CM_ "toyota_townace.dbc - Toyota Town Ace (2025, Taiwan) powertrain + chassis CAN, 500 kbps";
CM_ "Made 2026-11-17 from openpilot branch 2955 daihatsu_granmax_generated.dbc (802309d2f).";
CM_ "The Town Ace is the Toyota badge of the Daihatsu Gran Max (S403/S413); the Gran Max";
CM_ "DBC was itself built from a Town Ace highway capture (220676 frames, 69 IDs).";
CM_ "Changes from the Gran Max DBC, all measured on the car with lowcostPedal t10b_can_signals:";
CM_ "  TRANSMISSION.GEAR now covers all of byte 1 (R N D 2 L), PARK added (byte 0 bit 0).";
CM_ "  HANDBRAKE.HANDBRAKE_ENGAGED moved to byte 0 bit 0 (the old one sat on the checksum).";
CM_ "  WHEEL_SPEED_CLEAN.WHEELSPEED moved to bytes 5-6 (the old 13-bit field overflowed).";
CM_ "  MSG_199 renamed SPEED_2 with the speed in bytes 3-4.";
CM_ "Frame checksum is the Toyota scheme (file name starts with toyota_ so opendbc uses it).";
CM_ "MSG_xxx entries are not decoded. Scales not marked verified are still Ativa values.";

VERSION ""

NS_ :

BS_:

BU_: EON XXX INTERCEPTOR ANY ACTUATOR SAFETY

BO_ 8 STAYALIVE_1: 0 XXX

BO_ 51 STAYALIVE_2: 0 XXX

BO_ 160 MSG_0A0: 5 XXX
 SG_ CHECKSUM : 39|8@0+ (1,0) [0|255] "" XXX

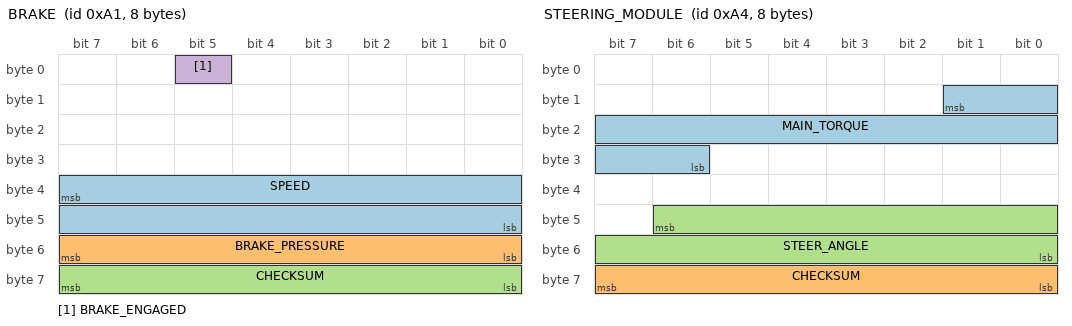
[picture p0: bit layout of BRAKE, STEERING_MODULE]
BO_ 161 BRAKE: 8 XXX
 SG_ SPEED : 39|16@0+ (0.01,0) [0|65535] "km/h" XXX
 SG_ BRAKE_PRESSURE : 48|8@1+ (0.005532,0) [0|255] "" XXX
 SG_ CHECKSUM : 63|8@0+ (1,0) [0|255] "" XXX
 SG_ BRAKE_ENGAGED : 5|1@0+ (1,0) [0|1] "" XXX

BO_ 164 STEERING_MODULE: 8 XXX
 SG_ MAIN_TORQUE : 9|12@0- (1,0) [0|65535] "" XXX
 SG_ CHECKSUM : 63|8@0+ (1,0) [0|255] "" XXX
 SG_ STEER_ANGLE : 46|15@0- (0.10047,0) [-500|500] "" XXX

BO_ 165 MSG_0A5: 4 XXX
 SG_ CHECKSUM : 31|8@0+ (1,0) [0|255] "" XXX

BO_ 308 MSG_134: 6 XXX
 SG_ CHECKSUM : 47|8@0+ (1,0) [0|255] "" XXX

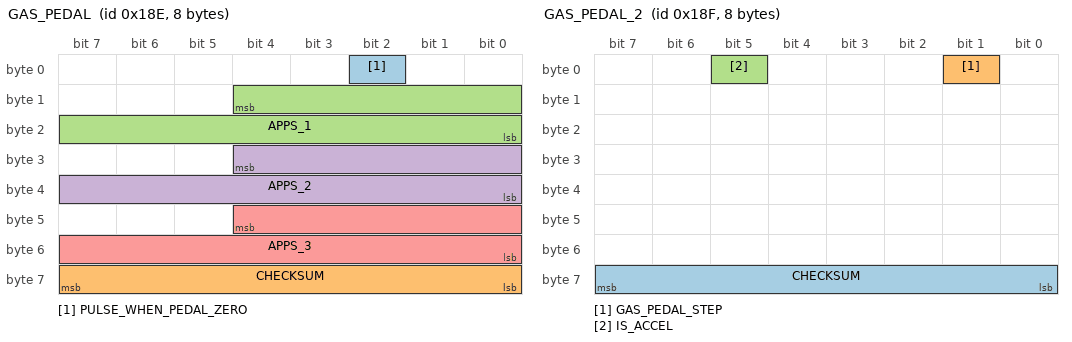
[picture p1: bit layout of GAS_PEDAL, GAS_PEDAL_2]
BO_ 398 GAS_PEDAL: 8 XXX
 SG_ PULSE_WHEN_PEDAL_ZERO : 2|1@0+ (1,0) [0|1] "" XXX
 SG_ CHECKSUM : 63|8@0+ (1,0) [0|255] "" XXX
 SG_ APPS_1 : 12|13@0+ (0.015625,0) [0|100] "%" XXX
 SG_ APPS_2 : 28|13@0+ (0.00006742,0) [0|1023] "" XXX
 SG_ APPS_3 : 44|13@0+ (1,0) [0|8191] "rpm" XXX

BO_ 399 GAS_PEDAL_2: 8 XXX
 SG_ CHECKSUM : 63|8@0+ (1,0) [0|255] "" XXX
 SG_ GAS_PEDAL_STEP : 1|1@0+ (1,0) [0|1] "" XXX
 SG_ IS_ACCEL : 5|1@0+ (1,0) [0|1] "" XXX

BO_ 400 MSG_190: 8 XXX
 SG_ CHECKSUM : 63|8@0+ (1,0) [0|255] "" XXX

BO_ 409 SPEED_2: 8 XXX
 SG_ CHECKSUM : 63|8@0+ (1,0) [0|255] "" XXX
 SG_ SPEED : 31|16@0+ (0.0103,0) [0|675] "km/h" XXX

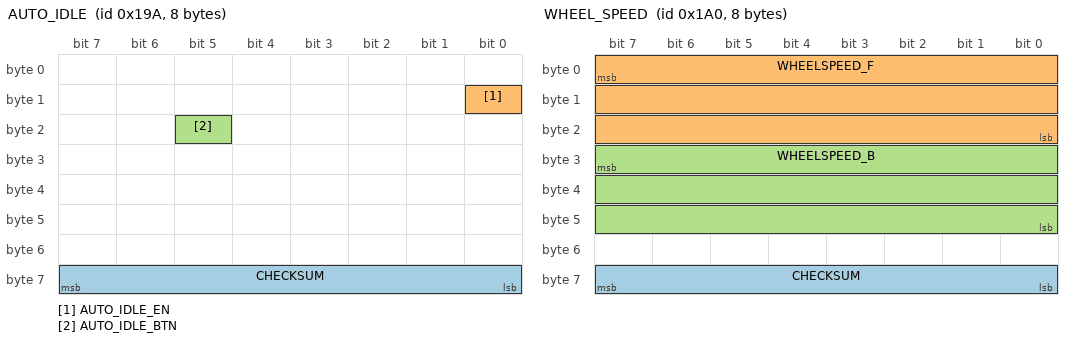
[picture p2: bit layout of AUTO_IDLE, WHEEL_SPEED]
BO_ 410 AUTO_IDLE: 8 XXX
 SG_ CHECKSUM : 63|8@0+ (1,0) [0|255] "" XXX
 SG_ AUTO_IDLE_EN : 8|1@1+ (1,0) [0|511] "" XXX
 SG_ AUTO_IDLE_BTN : 21|1@0+ (1,0) [0|1] "" XXX

BO_ 416 WHEEL_SPEED: 8 XXX
 SG_ CHECKSUM : 63|8@0+ (1,0) [0|255] "" XXX
 SG_ WHEELSPEED_F : 7|24@0+ (0.00001,0) [0|16777215] "" XXX
 SG_ WHEELSPEED_B : 31|24@0+ (0.00000250,0) [0|16777215] "" XXX

BO_ 417 MSG_1A1: 7 XXX
 SG_ CHECKSUM : 55|8@0+ (1,0) [0|255] "" XXX

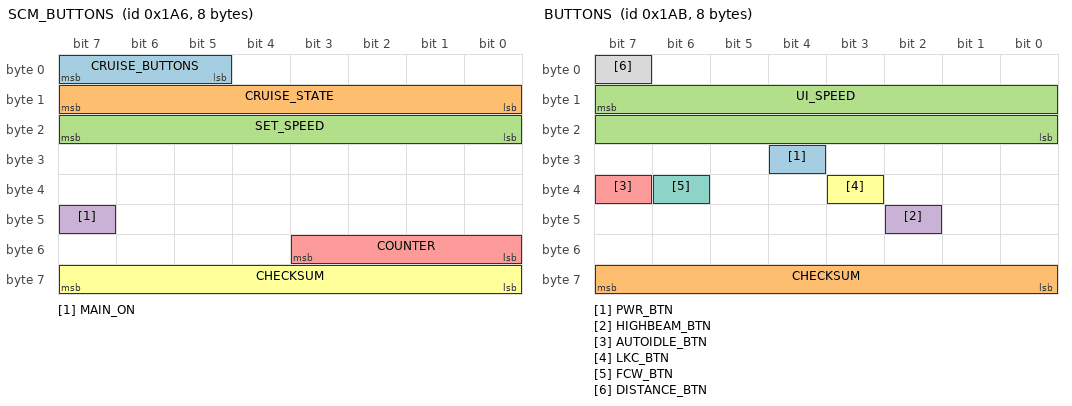
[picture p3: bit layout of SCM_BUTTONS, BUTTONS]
BO_ 422 SCM_BUTTONS: 8 INTERCEPTOR
 SG_ CRUISE_BUTTONS : 7|3@0+ (1,0) [0|7] "" XXX
 SG_ CRUISE_STATE : 15|8@0+ (1,0) [0|4] "" XXX
 SG_ SET_SPEED : 23|8@0+ (1,0) [0|255] "km/h" XXX
 SG_ MAIN_ON : 47|1@0+ (1,0) [0|1] "" XXX
 SG_ COUNTER : 51|4@0+ (1,0) [0|15] "" XXX
 SG_ CHECKSUM : 63|8@0+ (1,0) [0|255] "" XXX

BO_ 427 BUTTONS: 8 XXX
 SG_ PWR_BTN : 28|1@0+ (1,0) [0|1] "" XXX
 SG_ CHECKSUM : 63|8@0+ (1,0) [0|255] "" XXX
 SG_ UI_SPEED : 15|16@0+ (0.01,0) [0|65535] "" XXX
 SG_ HIGHBEAM_BTN : 42|1@0+ (1,0) [0|1] "" XXX
 SG_ AUTOIDLE_BTN : 39|1@0+ (1,0) [0|1] "" XXX
 SG_ LKC_BTN : 35|1@0+ (1,0) [0|1] "" XXX
 SG_ FCW_BTN : 38|1@1+ (1,0) [0|511] "" XXX
 SG_ DISTANCE_BTN : 7|1@0+ (1,0) [0|1] "" XXX

BO_ 429 MSG_1AD: 8 XXX
 SG_ CHECKSUM : 63|8@0+ (1,0) [0|255] "" XXX

BO_ 448 EPS_SHAFT_TORQUE: 4 XXX
 SG_ CHECKSUM : 31|8@0+ (1,0) [0|255] "" XXX
 SG_ STEERING_TORQUE : 8|8@1+ (1,0) [0|255] "" XXX

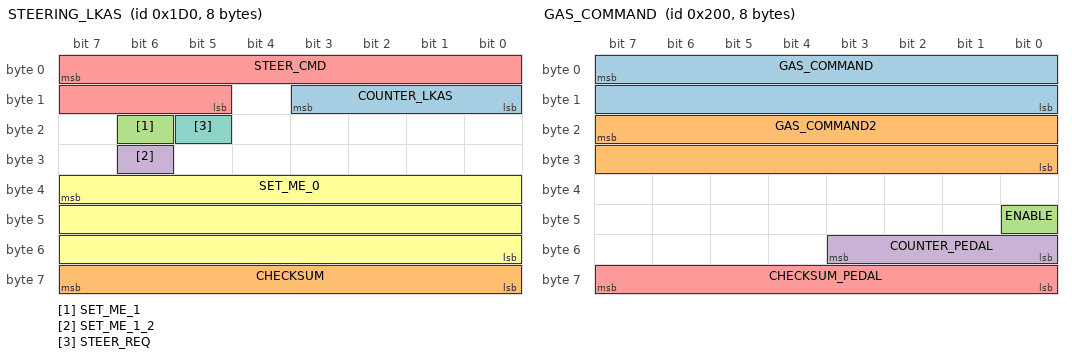
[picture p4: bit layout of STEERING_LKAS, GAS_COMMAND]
BO_ 464 STEERING_LKAS: 8 XXX
 SG_ COUNTER_LKAS : 11|4@0+ (1,0) [0|15] "" XXX
 SG_ CHECKSUM : 63|8@0+ (1,0) [0|255] "" XXX
 SG_ SET_ME_1 : 22|1@0+ (1,0) [0|1] "" XXX
 SG_ SET_ME_1_2 : 30|1@0+ (1,0) [0|1] "" XXX
 SG_ STEER_CMD : 7|11@0- (1,0) [0|255] "" XXX
 SG_ SET_ME_0 : 39|24@0+ (1,0) [0|16777215] "" XXX
 SG_ STEER_REQ : 21|1@0+ (1,0) [0|1] "" XXX

BO_ 496 MSG_1F0: 5 XXX
 SG_ CHECKSUM : 39|8@0+ (1,0) [0|255] "" XXX

BO_ 512 GAS_COMMAND: 8 SAFETY
 SG_ GAS_COMMAND : 7|16@0+ (1,0) [0|1] "" ACTUATOR
 SG_ GAS_COMMAND2 : 23|16@0+ (1,0) [0|1] "" ACTUATOR
 SG_ ENABLE : 40|1@0+ (1,0) [0|1] "" ACTUATOR
 SG_ COUNTER_PEDAL : 51|4@0+ (1,0) [0|15] "" ACTUATOR
 SG_ CHECKSUM_PEDAL : 63|8@0+ (1,0) [0|255] "" ACTUATOR

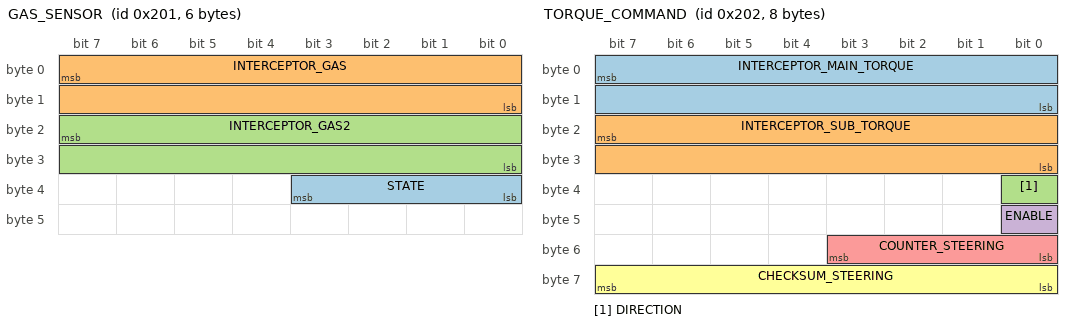
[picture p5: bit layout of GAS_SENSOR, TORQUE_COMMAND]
BO_ 513 GAS_SENSOR: 6 ACTUATOR
 SG_ STATE : 35|4@0+ (1,0) [0|15] "" SAFETY
 SG_ INTERCEPTOR_GAS : 7|16@0+ (0.0007,-0.342) [0|1] "" SAFETY
 SG_ INTERCEPTOR_GAS2 : 23|16@0+ (0.0007,-0.691) [0|1] "" SAFETY

BO_ 514 TORQUE_COMMAND: 8 SAFETY
 SG_ INTERCEPTOR_MAIN_TORQUE : 7|16@0+ (1,0) [0|1] "" ACTUATOR
 SG_ INTERCEPTOR_SUB_TORQUE : 23|16@0+ (1,0) [0|1] "" ACTUATOR
 SG_ DIRECTION : 32|1@0+ (1,0) [0|1] "" ACTUATOR
 SG_ ENABLE : 40|1@0+ (1,0) [0|1] "" ACTUATOR
 SG_ COUNTER_STEERING : 51|4@0+ (1,0) [0|15] "" ACTUATOR
 SG_ CHECKSUM_STEERING : 63|8@0+ (1,0) [0|255] "" ACTUATOR

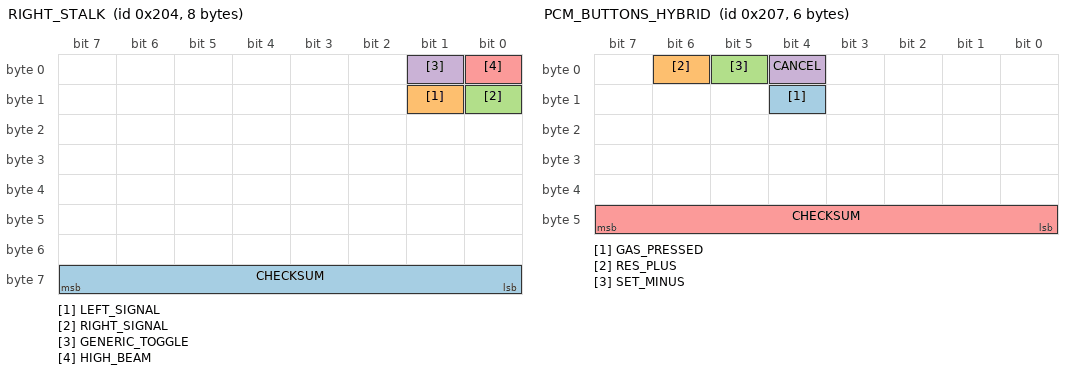
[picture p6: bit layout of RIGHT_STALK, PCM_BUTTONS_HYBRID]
BO_ 516 RIGHT_STALK: 8 XXX
 SG_ CHECKSUM : 63|8@0+ (1,0) [0|255] "" XXX
 SG_ LEFT_SIGNAL : 9|1@0+ (1,0) [0|1] "" XXX
 SG_ RIGHT_SIGNAL : 8|1@0+ (1,0) [0|1] "" XXX
 SG_ GENERIC_TOGGLE : 1|1@0+ (1,0) [0|1] "" XXX
 SG_ HIGH_BEAM : 0|1@0+ (1,0) [0|1] "" XXX

BO_ 519 PCM_BUTTONS_HYBRID: 6 XXX
 SG_ GAS_PRESSED : 12|1@0+ (1,0) [0|1] "" XXX
 SG_ RES_PLUS : 6|1@0+ (1,0) [0|1] "" XXX
 SG_ SET_MINUS : 5|1@0+ (1,0) [0|1] "" XXX
 SG_ CANCEL : 4|1@0+ (1,0) [0|1] "" XXX
 SG_ CHECKSUM : 47|8@0+ (1,0) [0|255] "" XXX

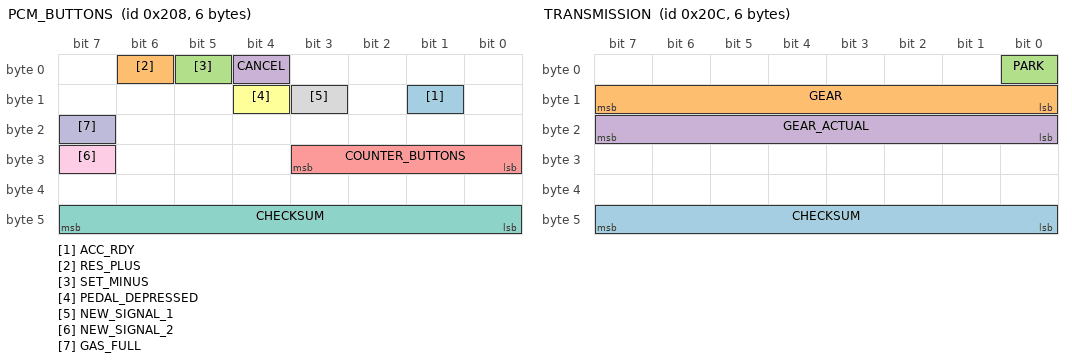
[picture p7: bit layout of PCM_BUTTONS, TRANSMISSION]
BO_ 520 PCM_BUTTONS: 6 XXX
 SG_ ACC_RDY : 9|1@0+ (1,0) [0|1] "" XXX
 SG_ RES_PLUS : 6|1@0+ (1,0) [0|1] "" XXX
 SG_ SET_MINUS : 5|1@0+ (1,0) [0|1] "" XXX
 SG_ CANCEL : 4|1@0+ (1,0) [0|1] "" XXX
 SG_ COUNTER_BUTTONS : 27|4@0+ (1,0) [0|15] "" XXX
 SG_ PEDAL_DEPRESSED : 12|1@0+ (1,0) [0|1] "" XXX
 SG_ CHECKSUM : 47|8@0+ (1,0) [0|255] "" XXX
 SG_ NEW_SIGNAL_1 : 11|1@0+ (1,0) [0|1] "" XXX
 SG_ NEW_SIGNAL_2 : 31|1@0+ (1,0) [0|1] "" XXX
 SG_ GAS_FULL : 23|1@0+ (1,0) [0|1] "" XXX

BO_ 524 TRANSMISSION: 6 XXX
 SG_ CHECKSUM : 47|8@0+ (1,0) [0|255] "" XXX
 SG_ GEAR : 15|8@0+ (1,0) [0|255] "" XXX
 SG_ PARK : 0|1@0+ (1,0) [0|1] "" XXX
 SG_ GEAR_ACTUAL : 23|8@0+ (1,0) [0|255] "" XXX

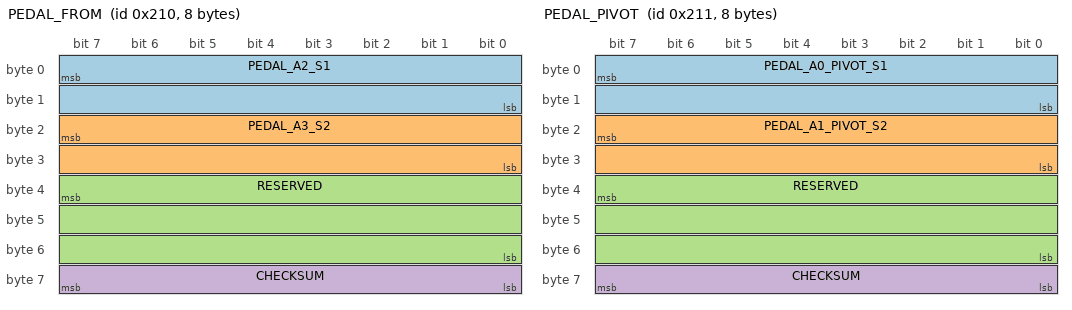
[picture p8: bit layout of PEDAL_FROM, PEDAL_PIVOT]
BO_ 528 PEDAL_FROM: 8 INTERCEPTOR
 SG_ PEDAL_A2_S1 : 7|16@0+ (0.0048875855,0) [0|5] "V" XXX
 SG_ PEDAL_A3_S2 : 23|16@0+ (0.0048875855,0) [0|5] "V" XXX
 SG_ RESERVED : 39|24@0+ (1,0) [0|0] "" XXX
 SG_ CHECKSUM : 63|8@0+ (1,0) [0|255] "" XXX

BO_ 529 PEDAL_PIVOT: 8 INTERCEPTOR
 SG_ PEDAL_A0_PIVOT_S1 : 7|16@0+ (0.0048875855,0) [0|5] "V" XXX
 SG_ PEDAL_A1_PIVOT_S2 : 23|16@0+ (0.0048875855,0) [0|5] "V" XXX
 SG_ RESERVED : 39|24@0+ (1,0) [0|0] "" XXX
 SG_ CHECKSUM : 63|8@0+ (1,0) [0|255] "" XXX

BO_ 608 WHEEL_SPEED_CLEAN: 8 XXX
 SG_ CHECKSUM : 63|8@0+ (1,0) [0|255] "" XXX
 SG_ WHEELSPEED : 47|16@0+ (0.0102,0) [0|668] "km/h" XXX

BO_ 609 MSG_261: 8 XXX
 SG_ CHECKSUM : 63|8@0+ (1,0) [0|255] "" XXX

BO_ 624 ADAS_AEB: 8 XXX
 SG_ CHECKSUM : 63|8@0+ (1,0) [0|255] "" XXX
 SG_ SET_ME_XC0 : 7|8@0+ (1,0) [0|255] "" XXX
 SG_ SET_ME_XFF_1 : 23|8@0+ (1,0) [0|255] "" XXX
 SG_ SET_ME_XFF_2 : 31|8@0+ (1,0) [0|255] "" XXX
 SG_ SET_ME_XFF_3 : 39|8@0+ (1,0) [0|255] "" XXX
 SG_ SET_ME_XFF_4 : 47|8@0+ (1,0) [0|255] "" XXX
 SG_ SET_ME_X15_1 : 15|8@0+ (1,0) [0|255] "" XXX
 SG_ SET_ME_X15_2 : 55|8@0+ (1,0) [0|255] "" XXX
 SG_ SET_ME_X60 : 63|8@0+ (1,0) [0|255] "" XXX

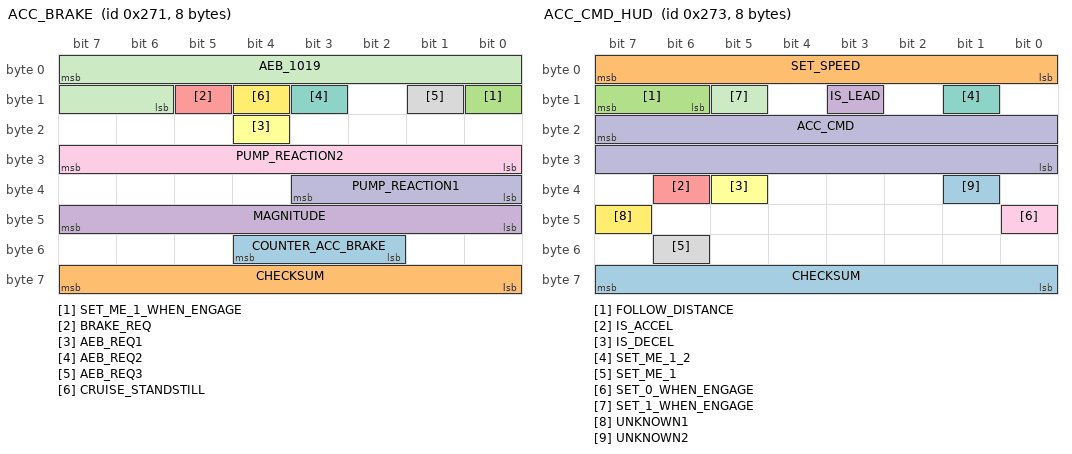
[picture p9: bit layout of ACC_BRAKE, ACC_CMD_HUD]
BO_ 625 ACC_BRAKE: 8 XXX
 SG_ COUNTER_ACC_BRAKE : 52|3@0+ (1,0) [0|255] "" XXX
 SG_ CHECKSUM : 63|8@0+ (1,0) [0|255] "" XXX
 SG_ SET_ME_1_WHEN_ENGAGE : 8|1@0+ (1,0) [0|1] "" XXX
 SG_ MAGNITUDE : 47|8@0+ (0.01,-2) [0|255] "" XXX
 SG_ BRAKE_REQ : 13|1@0+ (1,0) [0|1] "" XXX
 SG_ AEB_REQ1 : 20|1@0+ (1,0) [0|1] "" XXX
 SG_ AEB_REQ2 : 11|1@0+ (1,0) [0|1] "" XXX
 SG_ AEB_REQ3 : 9|1@0+ (1,0) [0|1] "" XXX
 SG_ PUMP_REACTION2 : 31|8@0- (0.1,0) [0|16777215] "" XXX
 SG_ PUMP_REACTION1 : 35|4@0+ (0.1,0) [0|1] "" XXX
 SG_ AEB_1019 : 7|10@0+ (1,0) [0|255] "" XXX
 SG_ CRUISE_STANDSTILL : 12|1@0+ (1,0) [0|1] "" XXX

BO_ 627 ACC_CMD_HUD: 8 XXX
 SG_ CHECKSUM : 63|8@0+ (1,0) [0|255] "" XXX
 SG_ SET_SPEED : 7|8@0+ (1,0) [0|255] "" XXX
 SG_ FOLLOW_DISTANCE : 15|2@0+ (1,0) [0|3] "" XXX
 SG_ IS_LEAD : 11|1@0+ (1,0) [0|1] "" XXX
 SG_ IS_ACCEL : 38|1@0+ (1,0) [0|1] "" XXX
 SG_ IS_DECEL : 37|1@0+ (1,0) [0|1] "" XXX
 SG_ SET_ME_1_2 : 9|1@0+ (1,0) [0|1] "" XXX
 SG_ SET_ME_1 : 54|1@0+ (1,0) [0|1] "" XXX
 SG_ SET_0_WHEN_ENGAGE : 40|1@0+ (1,0) [0|1] "" XXX
 SG_ ACC_CMD : 23|16@0+ (0.01,0) [0|127] "" XXX
 SG_ SET_1_WHEN_ENGAGE : 13|1@0+ (1,0) [0|1] "" XXX
 SG_ UNKNOWN1 : 47|1@0+ (1,0) [0|1] "" XXX
 SG_ UNKNOWN2 : 33|1@0+ (1,0) [0|1] "" XXX

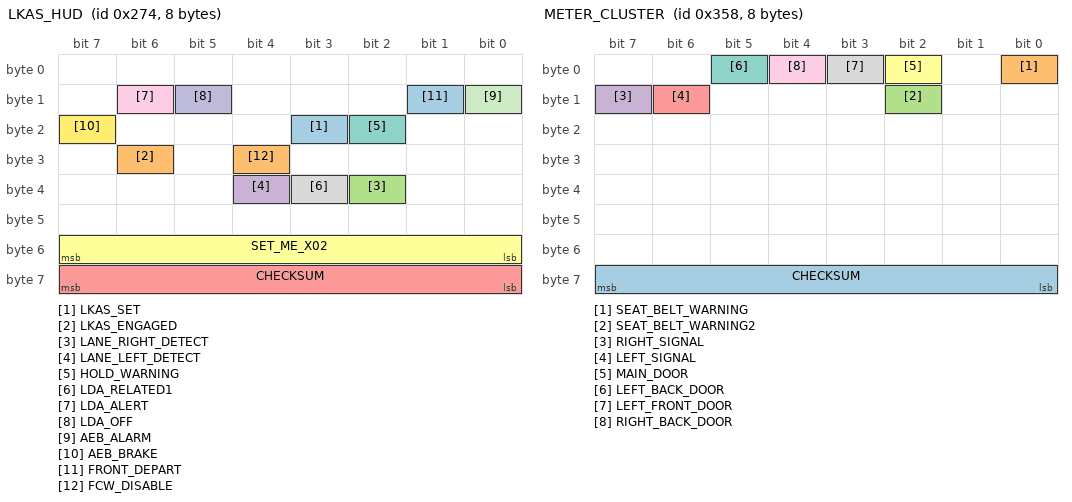
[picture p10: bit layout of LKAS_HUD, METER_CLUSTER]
BO_ 628 LKAS_HUD: 8 XXX
 SG_ LKAS_SET : 19|1@1+ (1,0) [0|3] "" XXX
 SG_ LKAS_ENGAGED : 30|1@0+ (1,0) [0|3] "" XXX
 SG_ LANE_RIGHT_DETECT : 34|1@0+ (1,0) [0|7] "" XXX
 SG_ LANE_LEFT_DETECT : 36|1@0+ (1,0) [0|1] "" XXX
 SG_ CHECKSUM : 63|8@0+ (1,0) [0|255] "" XXX
 SG_ SET_ME_X02 : 48|8@1+ (1,0) [0|3] "" XXX
 SG_ HOLD_WARNING : 18|1@0+ (1,0) [0|1] "" XXX
 SG_ LDA_RELATED1 : 35|1@0+ (1,0) [0|1] "" XXX
 SG_ LDA_ALERT : 14|1@0+ (1,0) [0|1] "" XXX
 SG_ LDA_OFF : 13|1@0+ (1,0) [0|1] "" XXX
 SG_ AEB_ALARM : 8|1@0+ (1,0) [0|1] "" XXX
 SG_ AEB_BRAKE : 23|1@0+ (1,0) [0|1] "" XXX
 SG_ FRONT_DEPART : 9|1@0+ (1,0) [0|1] "" XXX
 SG_ FCW_DISABLE : 28|1@0+ (1,0) [0|1] "" XXX

BO_ 736 MSG_2E0: 8 XXX
 SG_ CHECKSUM : 63|8@0+ (1,0) [0|255] "" XXX

BO_ 752 MSG_2F0: 8 XXX
 SG_ CHECKSUM : 63|8@0+ (1,0) [0|255] "" XXX

BO_ 834 BSM: 8 XXX
 SG_ BSM_CHIME : 23|1@0+ (1,0) [0|1] "" XXX

BO_ 848 MSG_350: 5 XXX
 SG_ CHECKSUM : 39|8@0+ (1,0) [0|255] "" XXX

BO_ 856 METER_CLUSTER: 8 XXX
 SG_ CHECKSUM : 63|8@0+ (1,0) [0|255] "" XXX
 SG_ SEAT_BELT_WARNING : 0|1@0+ (1,0) [0|1] "" XXX
 SG_ SEAT_BELT_WARNING2 : 10|1@0+ (1,0) [0|1] "" XXX
 SG_ RIGHT_SIGNAL : 15|1@0+ (1,0) [0|3] "" XXX
 SG_ LEFT_SIGNAL : 14|1@0+ (1,0) [0|3] "" XXX
 SG_ MAIN_DOOR : 2|1@1+ (1,0) [0|3] "" XXX
 SG_ LEFT_BACK_DOOR : 5|1@0+ (1,0) [0|1] "" XXX
 SG_ LEFT_FRONT_DOOR : 3|1@0+ (1,0) [0|1] "" XXX
 SG_ RIGHT_BACK_DOOR : 4|1@0+ (1,0) [0|1] "" XXX

BO_ 857 MSG_359: 4 XXX
 SG_ CHECKSUM : 31|8@0+ (1,0) [0|255] "" XXX

BO_ 900 HANDBRAKE: 4 XXX
 SG_ CHECKSUM : 31|8@0+ (1,0) [0|255] "" XXX
 SG_ HANDBRAKE_ENGAGED : 0|1@0+ (1,0) [0|1] "" XXX

BO_ 912 MSG_390: 4 XXX
 SG_ CHECKSUM : 31|8@0+ (1,0) [0|255] "" XXX

BO_ 976 MSG_3D0: 5 XXX
 SG_ CHECKSUM : 39|8@0+ (1,0) [0|255] "" XXX

BO_ 980 MSG_3D4: 8 XXX
 SG_ CHECKSUM : 63|8@0+ (1,0) [0|255] "" XXX

BO_ 1012 MSG_3F4: 7 XXX
 SG_ CHECKSUM : 55|8@0+ (1,0) [0|255] "" XXX

BO_ 1032 MSG_408: 8 XXX
 SG_ CHECKSUM : 63|8@0+ (1,0) [0|255] "" XXX

BO_ 1033 MSG_409: 8 XXX
 SG_ CHECKSUM : 63|8@0+ (1,0) [0|255] "" XXX

BO_ 1034 MSG_40A: 8 XXX

BO_ 1088 MSG_440: 8 XXX

BO_ 1090 MSG_442: 8 XXX

BO_ 1100 MSG_44C: 8 XXX

BO_ 1152 MSG_480: 8 XXX
 SG_ CHECKSUM : 63|8@0+ (1,0) [0|255] "" XXX

BO_ 1160 MSG_488: 4 XXX
 SG_ CHECKSUM : 31|8@0+ (1,0) [0|255] "" XXX

BO_ 1162 MSG_48A: 8 XXX

BO_ 1163 MSG_48B: 8 XXX

BO_ 1164 MSG_48C: 8 XXX

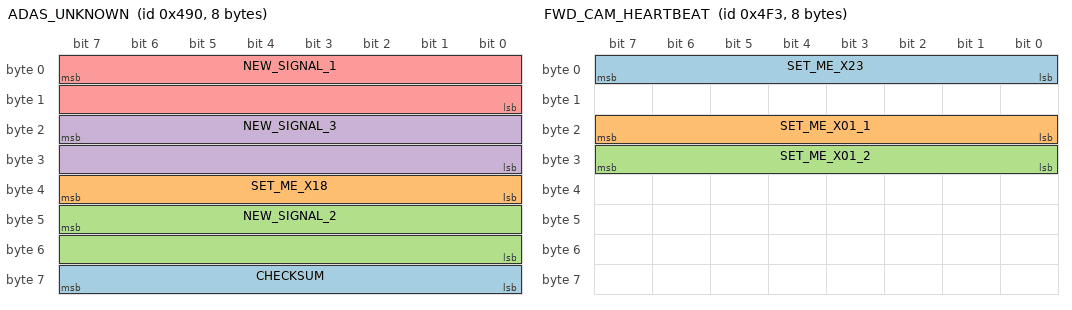
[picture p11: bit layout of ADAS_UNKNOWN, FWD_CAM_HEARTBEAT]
BO_ 1168 ADAS_UNKNOWN: 8 XXX
 SG_ CHECKSUM : 63|8@0+ (1,0) [0|255] "" XXX
 SG_ SET_ME_X18 : 39|8@0+ (1,0) [0|255] "" XXX
 SG_ NEW_SIGNAL_2 : 47|16@0- (1,0) [0|65535] "" XXX
 SG_ NEW_SIGNAL_3 : 23|16@0- (1,0) [0|65535] "" XXX
 SG_ NEW_SIGNAL_1 : 7|16@0- (1,0) [0|4294967295] "" XXX

BO_ 1176 MSG_498: 3 XXX
 SG_ CHECKSUM : 23|8@0+ (1,0) [0|255] "" XXX

BO_ 1188 MSG_4A4: 8 XXX
 SG_ CHECKSUM : 63|8@0+ (1,0) [0|255] "" XXX

BO_ 1200 MSG_4B0: 3 XXX
 SG_ CHECKSUM : 23|8@0+ (1,0) [0|255] "" XXX

BO_ 1217 MSG_4C1: 8 XXX

BO_ 1218 MSG_4C2: 8 XXX

BO_ 1219 MSG_4C3: 8 XXX

BO_ 1224 MSG_4C8: 8 XXX

BO_ 1245 MSG_4DD: 8 XXX

BO_ 1247 MSG_4DF: 8 XXX

BO_ 1248 MSG_4E0: 8 XXX

BO_ 1267 FWD_CAM_HEARTBEAT: 8 CAR
 SG_ SET_ME_X23 : 7|8@0+ (1,0) [0|255] "" ANY
 SG_ SET_ME_X01_1 : 23|8@0+ (1,0) [0|255] "" ANY
 SG_ SET_ME_X01_2 : 31|8@0+ (1,0) [0|255] "" ANY

BO_ 1271 MSG_4F7: 8 XXX

BO_ 1312 MSG_520: 8 XXX

BO_ 1408 MSG_580: 8 XXX

BO_ 1409 MSG_581: 8 XXX

BO_ 1410 MSG_582: 8 XXX

BO_ 1416 MSG_588: 8 XXX
 SG_ CHECKSUM : 63|8@0+ (1,0) [0|255] "" XXX

BO_ 1417 MSG_589: 8 XXX
 SG_ CHECKSUM : 63|8@0+ (1,0) [0|255] "" XXX

BO_ 1418 MSG_58A: 8 XXX
 SG_ CHECKSUM : 63|8@0+ (1,0) [0|255] "" XXX

BO_ 1434 MSG_59A: 8 XXX

BO_ 1435 MSG_59B: 8 XXX

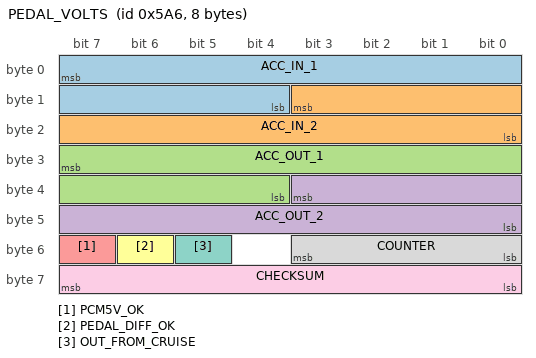
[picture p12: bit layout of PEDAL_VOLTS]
BO_ 1446 PEDAL_VOLTS: 8 INTERCEPTOR
 SG_ ACC_IN_1 : 7|12@0+ (0.002,0) [0|8.19] "V" XXX
 SG_ ACC_IN_2 : 11|12@0+ (0.002,0) [0|8.19] "V" XXX
 SG_ ACC_OUT_1 : 31|12@0+ (0.002,0) [0|8.19] "V" XXX
 SG_ ACC_OUT_2 : 35|12@0+ (0.002,0) [0|8.19] "V" XXX
 SG_ PCM5V_OK : 55|1@0+ (1,0) [0|1] "" XXX
 SG_ PEDAL_DIFF_OK : 54|1@0+ (1,0) [0|1] "" XXX
 SG_ OUT_FROM_CRUISE : 53|1@0+ (1,0) [0|1] "" XXX
 SG_ COUNTER : 51|4@0+ (1,0) [0|15] "" XXX
 SG_ CHECKSUM : 63|8@0+ (1,0) [0|255] "" XXX

BO_ 1447 PEDAL_DEBUG: 8 INTERCEPTOR
 SG_ STATE : 7|4@0+ (1,0) [0|15] "" XXX
 SG_ CTRL_SUB : 3|4@0+ (1,0) [0|15] "" XXX
 SG_ REASON : 15|8@0+ (1,0) [0|255] "" XXX
 SG_ RELAY_ON : 23|1@0+ (1,0) [0|1] "" XXX
 SG_ BRAKE : 22|1@0+ (1,0) [0|1] "" XXX
 SG_ GEAR_OK : 21|1@0+ (1,0) [0|1] "" XXX
 SG_ SPEED_OK : 20|1@0+ (1,0) [0|1] "" XXX
 SG_ HANDBRAKE : 19|1@0+ (1,0) [0|1] "" XXX
 SG_ DRIVER_ACTIVE : 18|1@0+ (1,0) [0|1] "" XXX
 SG_ OUT2_AT_MAX : 17|1@0+ (1,0) [0|1] "" XXX
 SG_ OUT_AT_FLOOR : 16|1@0+ (1,0) [0|1] "" XXX
 SG_ RESET_CAUSE : 31|4@0+ (1,0) [0|15] "" XXX
 SG_ BOOT_COUNT : 27|4@0+ (1,0) [0|15] "" XXX
 SG_ LOOP_MAX_MS : 39|8@0+ (1,0) [0|255] "ms" XXX
 SG_ SPEED_KPH : 47|8@0+ (1,0) [0|255] "km/h" XXX
 SG_ EVENT_SEQ : 55|4@0+ (1,0) [0|15] "" XXX
 SG_ COUNTER : 51|4@0+ (1,0) [0|15] "" XXX
 SG_ CHECKSUM : 63|8@0+ (1,0) [0|255] "" XXX

CM_ SG_ 161 SPEED "verified, km/h, same raw value as BUTTONS.UI_SPEED (dash)";
CM_ SG_ 161 BRAKE_ENGAGED "verified 2026-11-17: 1 = brake pedal pressed";
CM_ SG_ 161 BRAKE_PRESSURE "verified 2026-11-17/19 as pressure: raw 0 released, ~65 light, ~120 hard, 255 on the floor (8-bit limit, saturates); unit unknown";
CM_ SG_ 524 GEAR "verified 2026-11-17: one bit per lever position. R 0x80, N 0x40, D 0x20, 2 0x10, L 0x08. Reads 0 in P (use PARK) and for about 0.1 s while the lever moves between positions (0x04 seen once in P)";
CM_ SG_ 524 PARK "verified 2026-11-17: 1 = lever in P";
CM_ SG_ 524 GEAR_ACTUAL "NOT verified: 1 in D/2/L, 0 in P/R/N while parked, 2-4 while driving; looks like the gearbox gear";
CM_ SG_ 900 HANDBRAKE_ENGAGED "verified 2026-11-17: 1 = handbrake pulled";
CM_ SG_ 608 WHEELSPEED "km/h, tracks BRAKE.SPEED about 2% lower; scale from the capture, not calibrated";
CM_ SG_ 409 SPEED "km/h, tracks BRAKE.SPEED about 2-3% lower; scale from the capture, not calibrated";
CM_ SG_ 398 APPS_1 "verified 2026-11-17: accelerator pedal position 0-100 % (raw 0-6400), engine off and running";
CM_ SG_ 398 APPS_3 "verified 2026-11-24 (Fred, against the tachometer): engine speed, raw = rpm (1:1); 0 with the engine off";
CM_ SG_ 399 IS_ACCEL "verified 2026-11-17: name is inverted, 1 = accelerator released, 0 = pressed";
CM_ SG_ 520 GAS_FULL "seen 2026-11-17: 1 with the pedal on the floor, 0 at ~20 %; threshold not measured";
CM_ BO_ 422 "Sent by lowcostPedal (not by the car), 20 ms (50 Hz). Layout follows Honda CR-V 2016 SCM_BUTTONS (0x1A6) for the buttons; byte 7 is the Toyota checksum, byte 6 a 4-bit counter. Town Ace has no 0x1A6 of its own (checked on the 2026-09 captures). Added 2026-11-20, architecture A: the board runs cruise, this message only reports it";
CM_ SG_ 422 CRUISE_BUTTONS "cruise stalk button held now (from the J1-21 resistor ladder)";
CM_ SG_ 422 CRUISE_STATE "lowcostPedal cruise state machine";
CM_ SG_ 422 SET_SPEED "cruise set speed, km/h; 0 when no speed has been set";
CM_ SG_ 422 MAIN_ON "1 = stalk ON/OFF is ON (state READY, CRUISE or OVERRIDE)";
CM_ SG_ 422 COUNTER "0..15, +1 every frame";
CM_ SG_ 422 CHECKSUM "Toyota: (sum of bytes 0-6 + 0x01 + 0xA6 + 8) & 0xFF";
CM_ BO_ 1446 "Sent by lowcostPedal (not by the car), 50 ms (20 Hz), debug only, off when CAN_SEND_DEBUG 0. Shown by lowcostPedal_monitor_uno (UNO + LCD). 0x5A6 not seen on the Town Ace bus (2026-09 and 2026-11-17 captures). Byte 6 bit 4 reserved, sent 0. Values are sent as they are (no N/A code), 4095 = 8.19 V or more. Added 2026-11-22";
CM_ SG_ 1446 ACC_IN_1 "pedal sensor 1 at A0, ADC x AREF_V / 1023";
CM_ SG_ 1446 ACC_IN_2 "pedal sensor 2 at A1, ADC x AREF_V / 1023";
CM_ SG_ 1446 ACC_OUT_1 "output 1 to the PCM, from the measured duty -> mV table OUT1_TAB (commanded, not measured)";
CM_ SG_ 1446 ACC_OUT_2 "output 2 to the PCM, from OUT2_TAB (commanded, not measured)";
CM_ SG_ 1446 PCM5V_OK "1 = A2 PCM 5V >= PCM5V_MIN_ADC";
CM_ SG_ 1446 PEDAL_DIFF_OK "1 = IN2 - IN1 within PEDAL_DIFF_ADC +- PEDAL_DIFF_TOL_ADC";
CM_ SG_ 1446 OUT_FROM_CRUISE "1 = output comes from the cruise PID, 0 = pedal passthrough";
CM_ SG_ 1446 COUNTER "0..15, +1 every frame";
CM_ SG_ 1446 CHECKSUM "Toyota: (sum of bytes 0-6 + 0x05 + 0xA6 + 8) & 0xFF";
CM_ BO_ 1447 "Sent by lowcostPedal (not by the car), 50 ms (20 Hz), debug only, off when CAN_SEND_DEBUG 0; TX buffer 1, alternating with 0x5A6. Shown and logged by lowcostPedal_monitor_uno. 0x5A7 not seen on the Town Ace bus. Added 2026-11-23 to find which state the board is in when the MIL comes on while driving";
CM_ SG_ 1447 STATE "cruise state, same values as 0x1A6 CRUISE_STATE without OVERRIDE (see CTRL_SUB)";
CM_ SG_ 1447 CTRL_SUB "while CRUISE: cruise_ctrl sub-state; 15 = not cruising";
CM_ SG_ 1447 REASON "last cancel / refuse / fault reason (debug line last=), code list in pedal_debug.h";
CM_ SG_ 1447 RELAY_ON "1 = RLY_SW master switch on (D6), PCM gets the board outputs";
CM_ SG_ 1447 BRAKE "1 = brake light line (A6) above BRAKE_ON_ADC";
CM_ SG_ 1447 GEAR_OK "1 = 0x20C gear D/2/L (within GEAR_LOST_MS)";
CM_ SG_ 1447 SPEED_OK "1 = 0x0A1 speed received within CAN_SPEED_TIMEOUT_MS";
CM_ SG_ 1447 HANDBRAKE "1 = 0x384 handbrake pulled";
CM_ SG_ 1447 DRIVER_ACTIVE "1 = CRUISE with the driver overriding or coasting";
CM_ SG_ 1447 OUT2_AT_MAX "1 = since the previous 0x5A7 an output was cut at its cap (output 1 3548 mV, output 2 4348 mV; 0.8 V kept at the top, 2026-11-23)";
CM_ SG_ 1447 OUT_AT_FLOOR "1 = since the previous 0x5A7 an output was raised to its fixed floor (733 / 1534 mV)";
CM_ SG_ 1447 RESET_CAUSE "bit 3 watchdog: the WDT interrupt fired (a hang of ~125 ms) before this start and the loop never cleared the mark; normally the watchdog reset ~125 ms later, but an external reset inside that window also gives bit 3, and a watchdog reset whose interrupt never ran gives 0. Bits 2..0 brown-out / external / power-on only when a bootloader left MCUSR (the shipped optiboot clears it); 0 = unknown";
CM_ SG_ 1447 BOOT_COUNT "boot counter kept in EEPROM, low 4 bits; a change = the board restarted";
CM_ SG_ 1447 LOOP_MAX_MS "longest completed loop() since the previous 0x5A7, ms; 255 = 255 ms or more, or a watchdog stage-1 timeout the loop recovered from";
CM_ SG_ 1447 SPEED_KPH "speed the board uses (0x0A1), 0 when timed out";
CM_ SG_ 1447 EVENT_SEQ "+1 when the state at the end of a loop() differs from the previous loop (STATE, CTRL_SUB or REASON); two changes inside one loop count once";
CM_ SG_ 1447 COUNTER "0..15, +1 every frame";
CM_ SG_ 1447 CHECKSUM "Toyota: (sum of bytes 0-6 + 0x05 + 0xA7 + 8) & 0xFF";
VAL_ 627 FOLLOW_DISTANCE 2 "1bar" 1 "2bar" 0 "3bar" ;
VAL_ 513 STATE 5 "FAULT_TIMEOUT" 4 "FAULT_STARTUP" 3 "FAULT_SCE" 2 "FAULT_SEND" 1 "FAULT_BAD_CHECKSUM" 0 "NO_FAULT" ;
VAL_ 524 GEAR 128 "R" 64 "N" 32 "D" 16 "2" 8 "L" 4 "P" 0 "NONE" ;

CM_ BO_ 8 "not seen in the Gran Max capture";
CM_ BO_ 51 "not seen in the Gran Max capture";
CM_ BO_ 160 "static, 12.0 ms (83 Hz), 12729 frames, checksum=toyota";
CM_ BO_ 161 "dynamic, 12.0 ms (83 Hz), 12730 frames, checksum=toyota";
CM_ BO_ 164 "dynamic, 10.0 ms (100 Hz), 15272 frames, checksum=toyota";
CM_ BO_ 165 "static, 10.0 ms (100 Hz), 15272 frames, checksum=toyota";
CM_ BO_ 308 "dynamic, 12.3 ms (81 Hz), 12431 frames, checksum=toyota";
CM_ BO_ 398 "dynamic, 16.4 ms (61 Hz), 9324 frames, checksum=toyota";
CM_ BO_ 399 "dynamic, 16.4 ms (61 Hz), 9323 frames, checksum=toyota";
CM_ BO_ 400 "dynamic, 16.4 ms (61 Hz), 9324 frames, checksum=toyota";
CM_ BO_ 409 "dynamic, 16.4 ms (61 Hz), 9323 frames, checksum=toyota. Second vehicle speed, about 2-3% below BRAKE.SPEED; scale from the capture, not calibrated";
CM_ BO_ 410 "dynamic, 16.4 ms (61 Hz), 9324 frames, checksum=toyota";
CM_ BO_ 416 "dynamic, 18.0 ms (56 Hz), 8486 frames, checksum=toyota";
CM_ BO_ 417 "dynamic, 18.0 ms (56 Hz), 8487 frames, checksum=toyota";
CM_ BO_ 427 "dynamic, 20.0 ms (50 Hz), 7638 frames, checksum=toyota";
CM_ BO_ 429 "dynamic, 20.0 ms (50 Hz), 7645 frames, checksum=toyota";
CM_ BO_ 448 "dynamic, 24.0 ms (42 Hz), 6369 frames, checksum=toyota";
CM_ BO_ 464 "static, 25.0 ms (40 Hz), 6111 frames, checksum=toyota";
CM_ BO_ 496 "dynamic, 30.0 ms (33 Hz), 5092 frames, checksum=toyota";
CM_ BO_ 512 "not seen in the Gran Max capture";
CM_ BO_ 513 "not seen in the Gran Max capture";
CM_ BO_ 514 "not seen in the Gran Max capture";
CM_ BO_ 516 "dynamic, 30.0 ms (33 Hz), 5091 frames, checksum=toyota";
CM_ BO_ 519 "not seen in the Gran Max capture";
CM_ BO_ 520 "dynamic, 32.8 ms (31 Hz), 4662 frames, checksum=toyota";
CM_ BO_ 524 "dynamic, 32.8 ms (31 Hz), 4661 frames, checksum=toyota; lever position verified on the car 2026-11-17";
CM_ BO_ 528 "Arduino pedal board (pedal.ino), CAN_ID_IN 0x210, ADC A2/A3, 10.0 ms, checksum=toyota; Seen on the Town Ace bus 2026-11-17 (old pedal.ino board). lowcostPedal v0.1 uses 0x210/0x211 with a different layout, see lowcostPedal docs/open_issues.md";
CM_ BO_ 529 "Arduino pedal board (pedal.ino), CAN_ID_OUT 0x211, ADC A0/A1, 10.0 ms, checksum=toyota; Seen on the Town Ace bus 2026-11-17 (old pedal.ino board), see 528";
CM_ BO_ 608 "dynamic, 48.0 ms (21 Hz), 3183 frames, checksum=toyota";
CM_ BO_ 609 "dynamic, 48.0 ms (21 Hz), 3183 frames, checksum=toyota";
CM_ BO_ 624 "static, 50.0 ms (20 Hz), 3056 frames, checksum=toyota";
CM_ BO_ 625 "dynamic, 50.0 ms (20 Hz), 3056 frames, checksum=toyota";
CM_ BO_ 627 "static, 50.0 ms (20 Hz), 3056 frames, checksum=toyota";
CM_ BO_ 628 "static, 50.0 ms (20 Hz), 3056 frames, checksum=toyota";
CM_ BO_ 736 "static, 60.0 ms (17 Hz), 2544 frames, checksum=toyota";
CM_ BO_ 752 "dynamic, 65.5 ms (15 Hz), 2331 frames, checksum=toyota";
CM_ BO_ 834 "not seen in the Gran Max capture";
CM_ BO_ 848 "dynamic, 80.0 ms (12 Hz), 1910 frames, checksum=toyota";
CM_ BO_ 856 "dynamic, 79.9 ms (13 Hz), 1911 frames, checksum=toyota";
CM_ BO_ 857 "static, 79.9 ms (13 Hz), 1911 frames, checksum=toyota";
CM_ BO_ 900 "static, 100.0 ms (10 Hz), 1527 frames, checksum=toyota; handbrake verified on the car 2026-11-17";
CM_ BO_ 912 "static, 120.2 ms (8 Hz), 1272 frames, checksum=toyota";
CM_ BO_ 976 "dynamic, 204.8 ms (5 Hz), 746 frames, checksum=toyota";
CM_ BO_ 980 "static, 199.8 ms (5 Hz), 765 frames, checksum=toyota";
CM_ BO_ 1012 "dynamic, 262.2 ms (4 Hz), 583 frames, checksum=toyota";
CM_ BO_ 1032 "dynamic, 500.0 ms (2 Hz), 306 frames, checksum=toyota";
CM_ BO_ 1033 "static, 500.0 ms (2 Hz), 306 frames, checksum=toyota";
CM_ BO_ 1034 "dynamic, 499.6 ms (2 Hz), 306 frames, checksum=none";
CM_ BO_ 1088 "static, 259.8 ms (4 Hz), 589 frames, checksum=none";
CM_ BO_ 1090 "static, 260.0 ms (4 Hz), 589 frames, checksum=none";
CM_ BO_ 1100 "static, 260.1 ms (4 Hz), 590 frames, checksum=none";
CM_ BO_ 1152 "static, 1002.2 ms (1 Hz), 152 frames, checksum=toyota";
CM_ BO_ 1160 "static, 1024.2 ms (1 Hz), 150 frames, checksum=toyota";
CM_ BO_ 1162 "static, 4195.0 ms (0 Hz), 37 frames, checksum=none";
CM_ BO_ 1163 "static, 4195.0 ms (0 Hz), 37 frames, checksum=none";
CM_ BO_ 1164 "static, 4195.0 ms (0 Hz), 37 frames, checksum=none";
CM_ BO_ 1168 "dynamic, 100.0 ms (10 Hz), 1481 frames, checksum=toyota";
CM_ BO_ 1176 "static, 999.4 ms (1 Hz), 153 frames, checksum=toyota";
CM_ BO_ 1188 "dynamic, 999.2 ms (1 Hz), 153 frames, checksum=toyota";
CM_ BO_ 1200 "static, 1000.1 ms (1 Hz), 153 frames, checksum=toyota";
CM_ BO_ 1217 "static, 983.2 ms (1 Hz), 156 frames, checksum=none";
CM_ BO_ 1218 "static, 950.4 ms (1 Hz), 161 frames, checksum=none";
CM_ BO_ 1219 "static, 960.2 ms (1 Hz), 159 frames, checksum=none";
CM_ BO_ 1224 "static, 969.2 ms (1 Hz), 157 frames, checksum=none";
CM_ BO_ 1245 "static, 999.4 ms (1 Hz), 153 frames, checksum=none";
CM_ BO_ 1247 "static, 983.2 ms (1 Hz), 156 frames, checksum=none";
CM_ BO_ 1248 "static, 1000.1 ms (1 Hz), 153 frames, checksum=none";
CM_ BO_ 1267 "static, 960.1 ms (1 Hz), 159 frames, checksum=none";
CM_ BO_ 1271 "static, 1001.1 ms (1 Hz), 153 frames, checksum=none";
CM_ BO_ 1312 "dynamic, 1000.0 ms (1 Hz), 153 frames, checksum=none";
CM_ BO_ 1408 "static, 1532.0 ms (1 Hz), 100 frames, checksum=none";
CM_ BO_ 1409 "static, 1532.0 ms (1 Hz), 100 frames, checksum=none";
CM_ BO_ 1410 "static, 1532.0 ms (1 Hz), 100 frames, checksum=none";
CM_ BO_ 1416 "static, 5121.1 ms (0 Hz), 29 frames, checksum=toyota";
CM_ BO_ 1417 "static, 5120.8 ms (0 Hz), 29 frames, checksum=toyota";
CM_ BO_ 1418 "static, 5120.9 ms (0 Hz), 29 frames, checksum=toyota";
CM_ BO_ 1434 "static, 1000.0 ms (1 Hz), 153 frames, checksum=none";
CM_ BO_ 1435 "static, 1000.0 ms (1 Hz), 153 frames, checksum=none";
VAL_ 422 CRUISE_BUTTONS 4 "RES_PLUS" 3 "SET_MINUS" 2 "CANCEL" 1 "MAIN" 0 "NONE" ;
VAL_ 422 CRUISE_STATE 4 "FAULT" 3 "OVERRIDE" 2 "CRUISE" 1 "READY" 0 "OFF" ;
VAL_ 1447 STATE 4 "FAULT" 2 "CRUISE" 1 "READY" 0 "OFF" ;
VAL_ 1447 CTRL_SUB 15 "NONE" 3 "RECOVER" 2 "COAST" 1 "OVERRIDE" 0 "CONTROL" ;
VAL_ 1447 REASON 255 "OTHER" 25 "can init" 24 "pedal sensors" 23 "pcm 5v low" 22 "can 0x384 timeout" 21 "can 0x20C timeout" 20 "can 0x0A1 timeout" 11 "fault cleared" 10 "no last speed" 9 "pedal2 offset" 8 "speed range" 7 "master off" 6 "on/off" 5 "cancel" 4 "below 35 km/h" 3 "handbrake" 2 "gear not D/2/L" 1 "brake" 0 "NONE" ;
